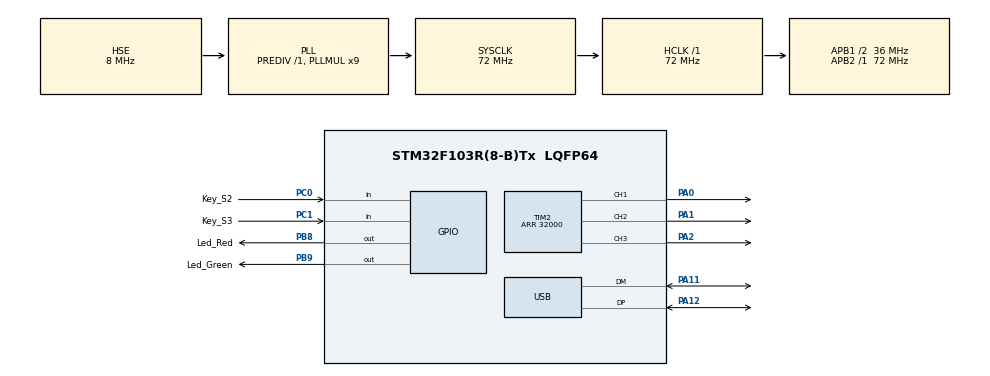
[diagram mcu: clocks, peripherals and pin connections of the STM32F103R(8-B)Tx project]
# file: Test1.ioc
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ADC1.AutoInjectedConv=DISABLE
ADC1.Channel-0\#ChannelRegularConversion=ADC_CHANNEL_TEMPSENSOR
ADC1.Channel-3\#ChannelRegularConversion=ADC_CHANNEL_VREFINT
ADC1.ContinuousConvMode=ENABLE
ADC1.InjNumberOfConversion=0
ADC1.InjectedDiscontinuousConvMode=DISABLE
ADC1.NbrOfConversion=2
ADC1.NbrOfConversionFlag=1
ADC1.Rank-0\#ChannelRegularConversion=1
ADC1.Rank-3\#ChannelRegularConversion=2
ADC1.SamplingTime-0\#ChannelRegularConversion=ADC_SAMPLETIME_239CYCLES_5
ADC1.SamplingTime-3\#ChannelRegularConversion=ADC_SAMPLETIME_239CYCLES_5
ADC1.master=1
FREERTOS.HEAP_NUMBER=1
FREERTOS.INCLUDE_vTaskDelete=0
FREERTOS.INCLUDE_xTaskAbortDelay=0
FREERTOS.INCLUDE_xTaskGetHandle=0
FREERTOS.MEMORY_ALLOCATION=0
FREERTOS.Queues01=QueUsbRead,128,uint8_t,NULL,Dynamic,NULL,NULL;QueUsbWrite,128,uint8_t,NULL,Dynamic,NULL,NULL
FREERTOS.Tasks01=defaultTask,0,128,StartDefaultTask,Default,NULL,Dynamic,NULL,NULL;TaskLedFlash,0,64,LedFlash,Default,NULL,Dynamic,NULL,NULL;TaskUsbRead,0,64,UsbRead,Default,NULL,Dynamic,NULL,NULL;TaskUsbWrite,0,64,UsbWrite,Default,NULL,Dynamic,NULL,NULL
FREERTOS.configMAX_PRIORITIES=5
FREERTOS.configMINIMAL_STACK_SIZE=64
FREERTOS.configTOTAL_HEAP_SIZE=6144
FREERTOS.configUSE_DAEMON_TASK_STARTUP_HOOK=0
Mcu.Family=STM32F1
Mcu.Name=STM32F103R(8-B)Tx
Mcu.Package=LQFP64
NVIC.PriorityGroup=NVIC_PRIORITYGROUP_4
NVIC.USB_LP_CAN1_RX0_IRQn=true\:5\:0\:false\:false\:true\:true
PA0-WKUP.GPIO_Speed=GPIO_SPEED_FREQ_HIGH
PA0-WKUP.Signal=S_TIM2_CH1_ETR
PA1.GPIO_Speed=GPIO_SPEED_FREQ_HIGH
PA1.Signal=S_TIM2_CH2
PA11.Mode=Device
PA11.Signal=USB_DM
PA12.Mode=Device
PA12.Signal=USB_DP
PA13.Mode=Trace_Asynchronous_SW
PA13.Signal=SYS_JTMS-SWDIO
PA14.Mode=Trace_Asynchronous_SW
PA14.Signal=SYS_JTCK-SWCLK
PA2.GPIO_Speed=GPIO_SPEED_FREQ_HIGH
PA2.Signal=S_TIM2_CH3
PB3.Mode=Trace_Asynchronous_SW
PB3.Signal=SYS_JTDO-TRACESWO
PB8.GPIO_Label=Led_Red
PB8.GPIO_Speed=GPIO_SPEED_FREQ_HIGH
PB8.Signal=GPIO_Output
PB9.GPIO_Label=Led_Green
PB9.GPIO_Speed=GPIO_SPEED_FREQ_HIGH
PB9.Signal=GPIO_Output
PC0.GPIO_Label=Key_S2
PC0.GPIO_PuPd=GPIO_PULLUP
PC0.Signal=GPIO_Input
PC1.GPIO_Label=Key_S3
PC1.GPIO_PuPd=GPIO_PULLUP
PC1.Signal=GPIO_Input
PC14-OSC32_IN.Mode=LSE-External-Oscillator
PC14-OSC32_IN.Signal=RCC_OSC32_IN
PC15-OSC32_OUT.Mode=LSE-External-Oscillator
PC15-OSC32_OUT.Signal=RCC_OSC32_OUT
PD0-OSC_IN.Mode=HSE-External-Oscillator
PD0-OSC_IN.Signal=RCC_OSC_IN
PD1-OSC_OUT.Mode=HSE-External-Oscillator
PD1-OSC_OUT.Signal=RCC_OSC_OUT
ProjectManager.HeapSize=0x200
ProjectManager.StackSize=0x400
ProjectManager.TargetToolchain=SW4STM32
RCC.ADCPresc=RCC_ADCPCLK2_DIV6
RCC.AHBCLKDivider=RCC_SYSCLK_DIV1
RCC.AHBFreq_Value=72000000
RCC.APB1CLKDivider=RCC_HCLK_DIV2
RCC.APB1Freq_Value=36000000
RCC.APB1TimFreq_Value=72000000
RCC.APB2CLKDivider=RCC_HCLK_DIV1
RCC.APB2Freq_Value=72000000
RCC.APB2TimFreq_Value=72000000
RCC.ClockTypeHCLK=RCC_CLOCKTYPE_HCLK
RCC.ClockTypePCLK1=RCC_CLOCKTYPE_PCLK1
RCC.ClockTypePCLK2=RCC_CLOCKTYPE_PCLK2
RCC.EnableHSE=true
RCC.EnableHSERTCDevisor=true
RCC.EnableLSE=true
RCC.EnableLSERTC=true
RCC.EnableMCOMultDivisor=false
RCC.HCLKFreq_Value=72000000
RCC.HSEState=RCC_HSE_ON
RCC.HSIState=RCC_HSI_ON
RCC.IWDGEnable=false
RCC.LSEState=RCC_LSE_ON
RCC.LSIState=RCC_LSI_OFF
RCC.MCOEnable=false
RCC.OscillatorTypeHSE=RCC_OSCILLATORTYPE_HSE
RCC.OscillatorTypeHSI=RCC_OSCILLATORTYPE_HSI
RCC.OscillatorTypeLSE=RCC_OSCILLATORTYPE_LSE
RCC.PLLMUL=RCC_PLL_MUL9
RCC.PLLSource=RCC_PLLSOURCE_HSE
RCC.PLLSourceVirtual=RCC_PLLSOURCE_HSE
RCC.PLLState=RCC_PLL_ON
RCC.RCC_PERIPHCLK_RTCVar=RCC_PERIPHCLK_RTC
RCC.RTCClockSelection=RCC_RTCCLKSOURCE_LSE
RCC.RTCEnable=true
RCC.SYSCLKFreq_VALUE=72000000
RCC.SYSCLKSource=RCC_SYSCLKSOURCE_PLLCLK
RCC.USBFreq_Value=48000000
RCC.USBPrescaler=RCC_USBCLKSOURCE_PLL_DIV1_5
RTC.Format=RTC_FORMAT_BCD
SH.S_TIM2_CH1_ETR.0=TIM2_CH1,PWM Generation1 CH1
SH.S_TIM2_CH2.0=TIM2_CH2,PWM Generation2 CH2
SH.S_TIM2_CH3.0=TIM2_CH3,PWM Generation3 CH3
TIM2.Channel-PWM\ Generation1\ CH1=TIM_CHANNEL_1
TIM2.Channel-PWM\ Generation2\ CH2=TIM_CHANNEL_2
TIM2.Channel-PWM\ Generation3\ CH3=TIM_CHANNEL_3
TIM2.ClockDivision=TIM_CLOCKDIVISION_DIV1
TIM2.Period=32000
USB.ep0_mps=DEP0CTL_MPS_64
USB_DEVICE.CLASS_NAME_FS=CDC
USB_DEVICE.USBD_CDC_INTERVAL=500
USB_DEVICE.USBD_HandleTypeDef_FS=hUsbDevice_USB_FS
USB_DEVICE.VirtualMode=Cdc
USB_DEVICE.VirtualModeFS=Cdc_FS
VP_ADC1_TempSens_Input.Mode=IN-TempSens
VP_ADC1_Vref_Input.Mode=IN-Vrefint
VP_FREERTOS_VS_ENABLE.Mode=Enabled
VP_RTC_VS_RTC_Activate.Mode=RTC_Enabled
VP_RTC_VS_RTC_Calendar.Mode=RTC_Calendar
VP_TIM2_VS_ClockSourceINT.Mode=Internal
VP_USB_DEVICE_VS_USB_DEVICE_CDC_FS.Mode=CDC_FS
board=test1

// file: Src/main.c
/**
  ******************************************************************************
  * File Name          : main.c
  * Description        : Main program body
  ******************************************************************************
  *
  * Copyright (c) 2017 STMicroelectronics International N.V.
  * All rights reserved.
  *
  * Redistribution and use in source and binary forms, with or without
  * modification, are permitted, provided that the following conditions are met:
  *
  * 1. Redistribution of source code must retain the above copyright notice,
  *    this list of conditions and the following disclaimer.
  * 2. Redistributions in binary form must reproduce the above copyright notice,
  *    this list of conditions and the following disclaimer in the documentation
  *    and/or other materials provided with the distribution.
  * 3. Neither the name of STMicroelectronics nor the names of other
  *    contributors to this software may be used to endorse or promote products
  *    derived from this software without specific written permission.
  * 4. This software, including modifications and/or derivative works of this
  *    software, must execute solely and exclusively on microcontroller or
  *    microprocessor devices manufactured by or for STMicroelectronics.
  * 5. Redistribution and use of this software other than as permitted under
  *    this license is void and will automatically terminate your rights under
  *    this license.
  *
  * THIS SOFTWARE IS PROVIDED BY STMICROELECTRONICS AND CONTRIBUTORS "AS IS"
  * AND ANY EXPRESS, IMPLIED OR STATUTORY WARRANTIES, INCLUDING, BUT NOT
  * LIMITED TO, THE IMPLIED WARRANTIES OF MERCHANTABILITY, FITNESS FOR A
  * PARTICULAR PURPOSE AND NON-INFRINGEMENT OF THIRD PARTY INTELLECTUAL PROPERTY
  * RIGHTS ARE DISCLAIMED TO THE FULLEST EXTENT PERMITTED BY LAW. IN NO EVENT
  * SHALL STMICROELECTRONICS OR CONTRIBUTORS BE LIABLE FOR ANY DIRECT, INDIRECT,
  * INCIDENTAL, SPECIAL, EXEMPLARY, OR CONSEQUENTIAL DAMAGES (INCLUDING, BUT NOT
  * LIMITED TO, PROCUREMENT OF SUBSTITUTE GOODS OR SERVICES; LOSS OF USE, DATA,
  * OR PROFITS; OR BUSINESS INTERRUPTION) HOWEVER CAUSED AND ON ANY THEORY OF
  * LIABILITY, WHETHER IN CONTRACT, STRICT LIABILITY, OR TORT (INCLUDING
  * NEGLIGENCE OR OTHERWISE) ARISING IN ANY WAY OUT OF THE USE OF THIS SOFTWARE,
  * EVEN IF ADVISED OF THE POSSIBILITY OF SUCH DAMAGE.
  *
  ******************************************************************************
  */
#include "main.h"
#include "stm32f1xx_hal.h"
#include "cmsis_os.h"
#include "usb_device.h"

ADC_HandleTypeDef hadc1;

RTC_HandleTypeDef hrtc;

TIM_HandleTypeDef htim2;

osThreadId defaultTaskHandle;
osThreadId TaskLedFlashHandle;
osThreadId TaskUsbReadHandle;
osThreadId TaskUsbWriteHandle;
osMessageQId QueUsbReadHandle;
osMessageQId QueUsbWriteHandle;

/* USER CODE BEGIN PV */
/* Private variables ---------------------------------------------------------*/

/* USER CODE END PV */

void SystemClock_Config(void);
void Error_Handler(void);
static void MX_GPIO_Init(void);
static void MX_ADC1_Init(void);
static void MX_RTC_Init(void);
static void MX_TIM2_Init(void);
void StartDefaultTask(void const * argument);
void LedFlash(void const * argument);
void UsbRead(void const * argument);
void UsbWrite(void const * argument);

void HAL_TIM_MspPostInit(TIM_HandleTypeDef *htim);

/* USER CODE BEGIN PFP */
/* Private function prototypes -----------------------------------------------*/

/* USER CODE END PFP */

int main(void)
{

  /* MCU Configuration----------------------------------------------------------*/

  /* Reset of all peripherals, Initializes the Flash interface and the Systick. */
  HAL_Init();

  /* Configure the system clock */
  SystemClock_Config();

  /* Initialize all configured peripherals */
  MX_GPIO_Init();
  MX_ADC1_Init();
  MX_RTC_Init();
  MX_TIM2_Init();

  /* Create the thread(s) */
  /* definition and creation of defaultTask */
  osThreadDef(defaultTask, StartDefaultTask, osPriorityNormal, 0, 128);
  defaultTaskHandle = osThreadCreate(osThread(defaultTask), NULL);

  /* definition and creation of TaskLedFlash */
  osThreadDef(TaskLedFlash, LedFlash, osPriorityNormal, 0, 64);
  TaskLedFlashHandle = osThreadCreate(osThread(TaskLedFlash), NULL);

  /* definition and creation of TaskUsbRead */
  osThreadDef(TaskUsbRead, UsbRead, osPriorityNormal, 0, 64);
  TaskUsbReadHandle = osThreadCreate(osThread(TaskUsbRead), NULL);

  /* definition and creation of TaskUsbWrite */
  osThreadDef(TaskUsbWrite, UsbWrite, osPriorityNormal, 0, 64);
  TaskUsbWriteHandle = osThreadCreate(osThread(TaskUsbWrite), NULL);

  /* Create the queue(s) */
  /* definition and creation of QueUsbRead */
  osMessageQDef(QueUsbRead, 128, uint8_t);
  QueUsbReadHandle = osMessageCreate(osMessageQ(QueUsbRead), NULL);

  /* definition and creation of QueUsbWrite */
  osMessageQDef(QueUsbWrite, 128, uint8_t);
  QueUsbWriteHandle = osMessageCreate(osMessageQ(QueUsbWrite), NULL);

  /* Start scheduler */
  osKernelStart();

  /* We should never get here as control is now taken by the scheduler */

  /* Infinite loop */
  while (1)
  {

  }

}

/** System Clock Configuration
*/
void SystemClock_Config(void)
{

  RCC_OscInitTypeDef RCC_OscInitStruct;
  RCC_ClkInitTypeDef RCC_ClkInitStruct;
  RCC_PeriphCLKInitTypeDef PeriphClkInit;

    /**Initializes the CPU, AHB and APB busses clocks
    */
  RCC_OscInitStruct.OscillatorType = RCC_OSCILLATORTYPE_HSI|RCC_OSCILLATORTYPE_HSE
                              |RCC_OSCILLATORTYPE_LSE;
  RCC_OscInitStruct.HSEState = RCC_HSE_ON;
  RCC_OscInitStruct.HSEPredivValue = RCC_HSE_PREDIV_DIV1;
  RCC_OscInitStruct.HSIState = RCC_HSI_ON;
  RCC_OscInitStruct.LSEState = RCC_LSE_ON;
  RCC_OscInitStruct.PLL.PLLState = RCC_PLL_ON;
  RCC_OscInitStruct.PLL.PLLSource = RCC_PLLSOURCE_HSE;
  RCC_OscInitStruct.PLL.PLLMUL = RCC_PLL_MUL9;
  if (HAL_RCC_OscConfig(&RCC_OscInitStruct) != HAL_OK)
  {
    Error_Handler();
  }

    /**Initializes the CPU, AHB and APB busses clocks
    */
  RCC_ClkInitStruct.ClockType = RCC_CLOCKTYPE_HCLK|RCC_CLOCKTYPE_SYSCLK
                              |RCC_CLOCKTYPE_PCLK1|RCC_CLOCKTYPE_PCLK2;
  RCC_ClkInitStruct.SYSCLKSource = RCC_SYSCLKSOURCE_PLLCLK;
  RCC_ClkInitStruct.AHBCLKDivider = RCC_SYSCLK_DIV1;
  RCC_ClkInitStruct.APB1CLKDivider = RCC_HCLK_DIV2;
  RCC_ClkInitStruct.APB2CLKDivider = RCC_HCLK_DIV1;

  if (HAL_RCC_ClockConfig(&RCC_ClkInitStruct, FLASH_LATENCY_2) != HAL_OK)
  {
    Error_Handler();
  }

  PeriphClkInit.PeriphClockSelection = RCC_PERIPHCLK_RTC|RCC_PERIPHCLK_ADC
                              |RCC_PERIPHCLK_USB;
  PeriphClkInit.RTCClockSelection = RCC_RTCCLKSOURCE_LSE;
  PeriphClkInit.AdcClockSelection = RCC_ADCPCLK2_DIV6;
  PeriphClkInit.UsbClockSelection = RCC_USBCLKSOURCE_PLL_DIV1_5;
  if (HAL_RCCEx_PeriphCLKConfig(&PeriphClkInit) != HAL_OK)
  {
    Error_Handler();
  }

    /**Configure the Systick interrupt time
    */
  HAL_SYSTICK_Config(HAL_RCC_GetHCLKFreq()/1000);

    /**Configure the Systick
    */
  HAL_SYSTICK_CLKSourceConfig(SYSTICK_CLKSOURCE_HCLK);

  /* SysTick_IRQn interrupt configuration */
  HAL_NVIC_SetPriority(SysTick_IRQn, 15, 0);
}

/* ADC1 init function */
static void MX_ADC1_Init(void)
{

  ADC_ChannelConfTypeDef sConfig;

    /**Common config
    */
  hadc1.Instance = ADC1;
  hadc1.Init.ScanConvMode = ADC_SCAN_ENABLE;
  hadc1.Init.ContinuousConvMode = ENABLE;
  hadc1.Init.DiscontinuousConvMode = DISABLE;
  hadc1.Init.ExternalTrigConv = ADC_SOFTWARE_START;
  hadc1.Init.DataAlign = ADC_DATAALIGN_RIGHT;
  hadc1.Init.NbrOfConversion = 2;
  if (HAL_ADC_Init(&hadc1) != HAL_OK)
  {
    Error_Handler();
  }

    /**Configure Regular Channel
    */
  sConfig.Channel = ADC_CHANNEL_TEMPSENSOR;
  sConfig.Rank = 1;
  sConfig.SamplingTime = ADC_SAMPLETIME_239CYCLES_5;
  if (HAL_ADC_ConfigChannel(&hadc1, &sConfig) != HAL_OK)
  {
    Error_Handler();
  }

    /**Configure Regular Channel
    */
  sConfig.Channel = ADC_CHANNEL_VREFINT;
  sConfig.Rank = 2;
  if (HAL_ADC_ConfigChannel(&hadc1, &sConfig) != HAL_OK)
  {
    Error_Handler();
  }

}

/* RTC init function */
static void MX_RTC_Init(void)
{

  RTC_TimeTypeDef sTime;
  RTC_DateTypeDef DateToUpdate;

    /**Initialize RTC Only
    */
  hrtc.Instance = RTC;
  hrtc.Init.AsynchPrediv = RTC_AUTO_1_SECOND;
  hrtc.Init.OutPut = RTC_OUTPUTSOURCE_ALARM;
  if (HAL_RTC_Init(&hrtc) != HAL_OK)
  {
    Error_Handler();
  }

    /**Initialize RTC and set the Time and Date
    */
  if(HAL_RTCEx_BKUPRead(&hrtc, RTC_BKP_DR1) != 0x32F2){
  sTime.Hours = 0x1;
  sTime.Minutes = 0x0;
  sTime.Seconds = 0x0;

  if (HAL_RTC_SetTime(&hrtc, &sTime, RTC_FORMAT_BCD) != HAL_OK)
  {
    Error_Handler();
  }

  DateToUpdate.WeekDay = RTC_WEEKDAY_MONDAY;
  DateToUpdate.Month = RTC_MONTH_JANUARY;
  DateToUpdate.Date = 0x1;
  DateToUpdate.Year = 0x0;

  if (HAL_RTC_SetDate(&hrtc, &DateToUpdate, RTC_FORMAT_BCD) != HAL_OK)
  {
    Error_Handler();
  }

    HAL_RTCEx_BKUPWrite(&hrtc,RTC_BKP_DR1,0x32F2);
  }

}

/* TIM2 init function */
static void MX_TIM2_Init(void)
{

  TIM_ClockConfigTypeDef sClockSourceConfig;
  TIM_MasterConfigTypeDef sMasterConfig;
  TIM_OC_InitTypeDef sConfigOC;

  htim2.Instance = TIM2;
  htim2.Init.Prescaler = 0;
  htim2.Init.CounterMode = TIM_COUNTERMODE_UP;
  htim2.Init.Period = 32000;
  htim2.Init.ClockDivision = TIM_CLOCKDIVISION_DIV1;
  if (HAL_TIM_Base_Init(&htim2) != HAL_OK)
  {
    Error_Handler();
  }

  sClockSourceConfig.ClockSource = TIM_CLOCKSOURCE_INTERNAL;
  if (HAL_TIM_ConfigClockSource(&htim2, &sClockSourceConfig) != HAL_OK)
  {
    Error_Handler();
  }

  if (HAL_TIM_PWM_Init(&htim2) != HAL_OK)
  {
    Error_Handler();
  }

  sMasterConfig.MasterOutputTrigger = TIM_TRGO_RESET;
  sMasterConfig.MasterSlaveMode = TIM_MASTERSLAVEMODE_DISABLE;
  if (HAL_TIMEx_MasterConfigSynchronization(&htim2, &sMasterConfig) != HAL_OK)
  {
    Error_Handler();
  }

  sConfigOC.OCMode = TIM_OCMODE_PWM1;
  sConfigOC.Pulse = 0;
  sConfigOC.OCPolarity = TIM_OCPOLARITY_HIGH;
  sConfigOC.OCFastMode = TIM_OCFAST_DISABLE;
  if (HAL_TIM_PWM_ConfigChannel(&htim2, &sConfigOC, TIM_CHANNEL_1) != HAL_OK)
  {
    Error_Handler();
  }

  if (HAL_TIM_PWM_ConfigChannel(&htim2, &sConfigOC, TIM_CHANNEL_2) != HAL_OK)
  {
    Error_Handler();
  }

  if (HAL_TIM_PWM_ConfigChannel(&htim2, &sConfigOC, TIM_CHANNEL_3) != HAL_OK)
  {
    Error_Handler();
  }

  HAL_TIM_MspPostInit(&htim2);

}

/** Configure pins as
        * Analog
        * Input
        * Output
        * EVENT_OUT
        * EXTI
*/
static void MX_GPIO_Init(void)
{

  GPIO_InitTypeDef GPIO_InitStruct;

  /* GPIO Ports Clock Enable */
  __HAL_RCC_GPIOC_CLK_ENABLE();
  __HAL_RCC_GPIOD_CLK_ENABLE();
  __HAL_RCC_GPIOA_CLK_ENABLE();
  __HAL_RCC_GPIOB_CLK_ENABLE();

  /*Configure GPIO pin Output Level */
  HAL_GPIO_WritePin(GPIOB, Led_Red_Pin|Led_Green_Pin, GPIO_PIN_RESET);

  /*Configure GPIO pins : Key_S2_Pin Key_S3_Pin */
  GPIO_InitStruct.Pin = Key_S2_Pin|Key_S3_Pin;
  GPIO_InitStruct.Mode = GPIO_MODE_INPUT;
  GPIO_InitStruct.Pull = GPIO_PULLUP;
  HAL_GPIO_Init(GPIOC, &GPIO_InitStruct);

  /*Configure GPIO pins : Led_Red_Pin Led_Green_Pin */
  GPIO_InitStruct.Pin = Led_Red_Pin|Led_Green_Pin;
  GPIO_InitStruct.Mode = GPIO_MODE_OUTPUT_PP;
  GPIO_InitStruct.Speed = GPIO_SPEED_FREQ_HIGH;
  HAL_GPIO_Init(GPIOB, &GPIO_InitStruct);

}

/* StartDefaultTask function */
void StartDefaultTask(void const * argument)
{
  /* init code for USB_DEVICE */
  MX_USB_DEVICE_Init();

  /* USER CODE BEGIN 5 */
  HAL_GPIO_WritePin(Led_Red_GPIO_Port, Led_Red_Pin, GPIO_PIN_SET);   // Red Led off after usb init
  /* Infinite loop */
  for(;;)
  {
    osDelay(1);
  }
  /* USER CODE END 5 */
}

/* LedFlash function */
void LedFlash(void const * argument)
{
  /* USER CODE BEGIN LedFlash */
  /* Infinite loop */
  for(;;)
  {
	HAL_GPIO_TogglePin(Led_Green_GPIO_Port, Led_Green_Pin); //Toggle Green Led 1/2 sec
	osDelay(500);
  }
  /* USER CODE END LedFlash */
}

/* UsbRead function */
void UsbRead(void const * argument)
{
  for(;;)
  {
    osDelay(1);
  }
}

/* UsbWrite function */
void UsbWrite(void const * argument)
{
  for(;;)
  {
    osDelay(1);
  }
}

void Error_Handler(void)
{
  /* USER CODE BEGIN Error_Handler */
  /* User can add his own implementation to report the HAL error return state */
	HAL_GPIO_WritePin(Led_Red_GPIO_Port, Led_Red_Pin, GPIO_PIN_RESET); // Led Red on for error state
  while(1)
  {
  }
  /* USER CODE END Error_Handler */
}

/************************ (C) COPYRIGHT STMicroelectronics *****END OF FILE****/
